# IVA_CM_CORE register map
Vendor: Texas Instruments
Peripheral module from a debugger description file (folder omap5430_ES2_PUBLIC).
Registers are 32-bit, access per field, reset 0x3 unless marked. A register's access mark holds for its fields unless they carry their own. Offsets are as the file gives them; lines under a group give offsets from that group; [hi:lo] are bit positions; {n}, {i} and the like mark numbered series; 'fields as' and 'values as' point back to an identical list; <NAME> marks a mode.

## IVA_CM_CORE
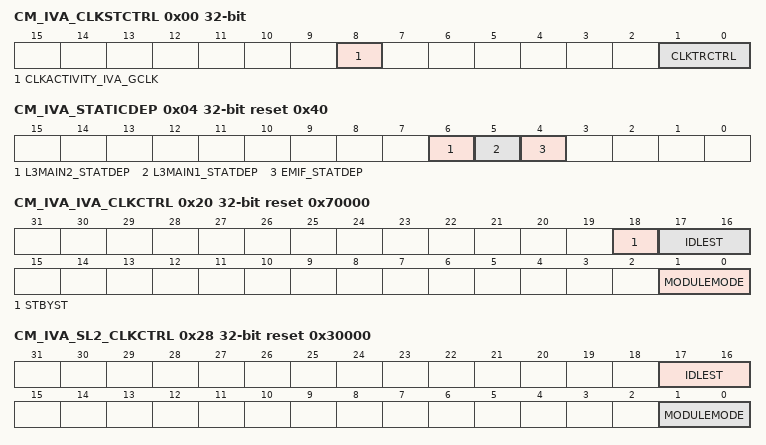
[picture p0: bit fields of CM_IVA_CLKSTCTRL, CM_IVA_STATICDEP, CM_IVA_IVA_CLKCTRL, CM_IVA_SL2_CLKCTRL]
0x00 CM_IVA_CLKSTCTRL — This register enables the IVA domain power state transition. It controls the HW supervised domain power state transition between ON-ACTIVE and ON-INACTIVE states. It also holds 1 status bit per clock input of the domain.
  [8] CLKACTIVITY_IVA_GCLK ro — This field indicates the state of the IVA_GCLK clock input of the domain. [warm reset insensitive]
    0=Inact (Corresponding clock is definitely gated); 1=Act (Corresponding clock is running or gating/ungating transition is on-going)
  [1:0] CLKTRCTRL rw — Controls the clock state transition of the IVA clock domain.
    0=NO_SLEEP (NO_SLEEP: Sleep transition cannot be initiated. Wakeup transition may however occur.); 1=SW_SLEEP (SW_SLEEP: Start a software forced sleep transition on the domain.); 2=SW_WKUP (SW_WKUP: Start a software forced wake-up transition on the domain.); 3=HW_AUTO (HW_AUTO: Automatic transition is enabled. Sleep and wakeup transition are based upon hardware conditions.)
0x04 CM_IVA_STATICDEP reset 0x40 — This register controls the static domain depedencies from IVA domain towards 'target' domains. It is relevant only for domain having system initiator(s).
  [6] L3MAIN2_STATDEP ro — Static dependency towards L3_MAIN2 clock domain
    1=Enabled (Dependency is enabled)
  [5] L3MAIN1_STATDEP rw — Static dependency towards L3_MAIN1 clock domain
    0=Disabled (Dependency is disabled); 1=Enabled (Dependency is enabled)
  [4] EMIF_STATDEP rw — Static dependency towards EMIF clock domain
    values as L3MAIN1_STATDEP
0x08 CM_IVA_DYNAMICDEP ro reset 0x0 — This register controls the dynamic domain depedencies from IVA domain towards 'target' domains. It is relevant only for domain having INTRCONN master port(s).
  [6] L3MAIN2_DYNDEP — Dynamic dependency towards L3_MAIN2 clock domain
    0=Disabled (Dependency is disabled)
0x20 CM_IVA_IVA_CLKCTRL reset 0x70000 — This register manages the IVA clocks.
  [18] STBYST ro — Module standby status. [warm reset insensitive]
    0=Func (Module is functional (not in standby)); 1=Standby (Module is in standby)
  [17:16] IDLEST ro — Module idle status. [warm reset insensitive]
    0=Func (Module is fully functional, including INTRCONN); 1=Trans (Module is performing transition: wakeup, or sleep, or sleep abortion); 2=Idle (Module is in Idle mode (only INTRCONN part). It is functional if using separate functional clock); 3=Disable (Module is disabled and cannot be accessed)
  [1:0] MODULEMODE rw — Control the way mandatory clocks are managed.
    0=DISABLED (Module is disable by SW. Any INTRCONN access to module results in an error, except if resulting from a module wakeup (asynchronous wakeup).); 1=RESERVED (Module is managed automatically by HW according to clock domain transition. A clock domain sleep transition put module into idle. A wakeup domain transition put it back into function. If[1:0] CLKTRCTRL = 0x3 (HW_AUTO), any INTRCONN access to module is always granted. Module clocks may be gated according to the clock domain state.)
0x28 CM_IVA_SL2_CLKCTRL reset 0x30000 — This register manages the SL2 clocks.
  [17:16] IDLEST ro — Module idle status. [warm reset insensitive]
    values as CM_IVA_IVA_CLKCTRL.IDLEST
  [1:0] MODULEMODE rw — Control the way mandatory clocks are managed.
    values as CM_IVA_IVA_CLKCTRL.MODULEMODE
